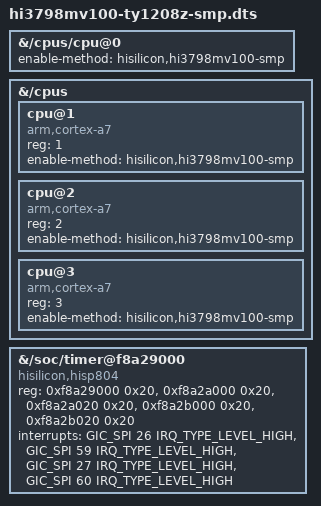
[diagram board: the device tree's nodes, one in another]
// SPDX-License-Identifier: GPL-2.0-only
#include "hi3798mv100-ty1208z-diagnostic.dts"

/* Four-core profile using the public HiSilicon CPU and hisp804 layout. */
&{/cpus/cpu@0} {
	enable-method = "hisilicon,hi3798mv100-smp";
};

&{/cpus} {
	cpu@1 {
		device_type = "cpu";
		compatible = "arm,cortex-a7";
		reg = <1>;
		enable-method = "hisilicon,hi3798mv100-smp";
	};
	cpu@2 {
		device_type = "cpu";
		compatible = "arm,cortex-a7";
		reg = <2>;
		enable-method = "hisilicon,hi3798mv100-smp";
	};
	cpu@3 {
		device_type = "cpu";
		compatible = "arm,cortex-a7";
		reg = <3>;
		enable-method = "hisilicon,hi3798mv100-smp";
	};
};

&{/soc/timer@f8a29000} {
	compatible = "hisilicon,hisp804";
	reg = <0xf8a29000 0x20>,
	      <0xf8a2a000 0x20>, <0xf8a2a020 0x20>,
	      <0xf8a2b000 0x20>, <0xf8a2b020 0x20>;
	interrupts = <GIC_SPI 26 IRQ_TYPE_LEVEL_HIGH>,
		     <GIC_SPI 59 IRQ_TYPE_LEVEL_HIGH>,
		     <GIC_SPI 27 IRQ_TYPE_LEVEL_HIGH>,
		     <GIC_SPI 60 IRQ_TYPE_LEVEL_HIGH>;
};
